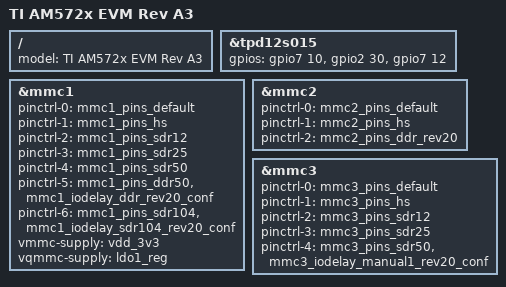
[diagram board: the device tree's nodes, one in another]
/*
 * Copyright (C) 2016 Texas Instruments Incorporated - http://www.ti.com/
 *
 * This program is free software; you can redistribute it and/or modify
 * it under the terms of the GNU General Public License version 2 as
 * published by the Free Software Foundation.
 */

#include "am57xx-beagle-x15-common.dtsi"
#include "am57xx-evm-common.dtsi"
#include "am57xx-industrial-grade.dtsi"
#include "am57xx-cmem.dtsi"

/ {
	model = "TI AM572x EVM Rev A3";
};

&tpd12s015 {
	gpios = <&gpio7 10 GPIO_ACTIVE_HIGH>,	/* gpio7_10, CT CP HPD */
		<&gpio2 30 GPIO_ACTIVE_HIGH>,	/* gpio2_30, LS OE */
		<&gpio7 12 GPIO_ACTIVE_HIGH>;	/* gpio7_12/sp1_cs2, HPD */
};

&mmc1 {
	pinctrl-names = "default", "hs", "sdr12", "sdr25", "sdr50", "ddr50", "sdr104";
	pinctrl-0 = <&mmc1_pins_default>;
	pinctrl-1 = <&mmc1_pins_hs>;
	pinctrl-2 = <&mmc1_pins_sdr12>;
	pinctrl-3 = <&mmc1_pins_sdr25>;
	pinctrl-4 = <&mmc1_pins_sdr50>;
	pinctrl-5 = <&mmc1_pins_ddr50 &mmc1_iodelay_ddr_rev20_conf>;
	pinctrl-6 = <&mmc1_pins_sdr104 &mmc1_iodelay_sdr104_rev20_conf>;
	vmmc-supply = <&vdd_3v3>;
	vqmmc-supply = <&ldo1_reg>;
};

&mmc2 {
	pinctrl-names = "default", "hs", "ddr_1_8v";
	pinctrl-0 = <&mmc2_pins_default>;
	pinctrl-1 = <&mmc2_pins_hs>;
	pinctrl-2 = <&mmc2_pins_ddr_rev20>;
};

&mmc3 {
	pinctrl-names = "default", "hs", "sdr12", "sdr25", "sdr50";
	pinctrl-0 = <&mmc3_pins_default>;
	pinctrl-1 = <&mmc3_pins_hs>;
	pinctrl-2 = <&mmc3_pins_sdr12>;
	pinctrl-3 = <&mmc3_pins_sdr25>;
	pinctrl-4 = <&mmc3_pins_sdr50 &mmc3_iodelay_manual1_rev20_conf>;
};
